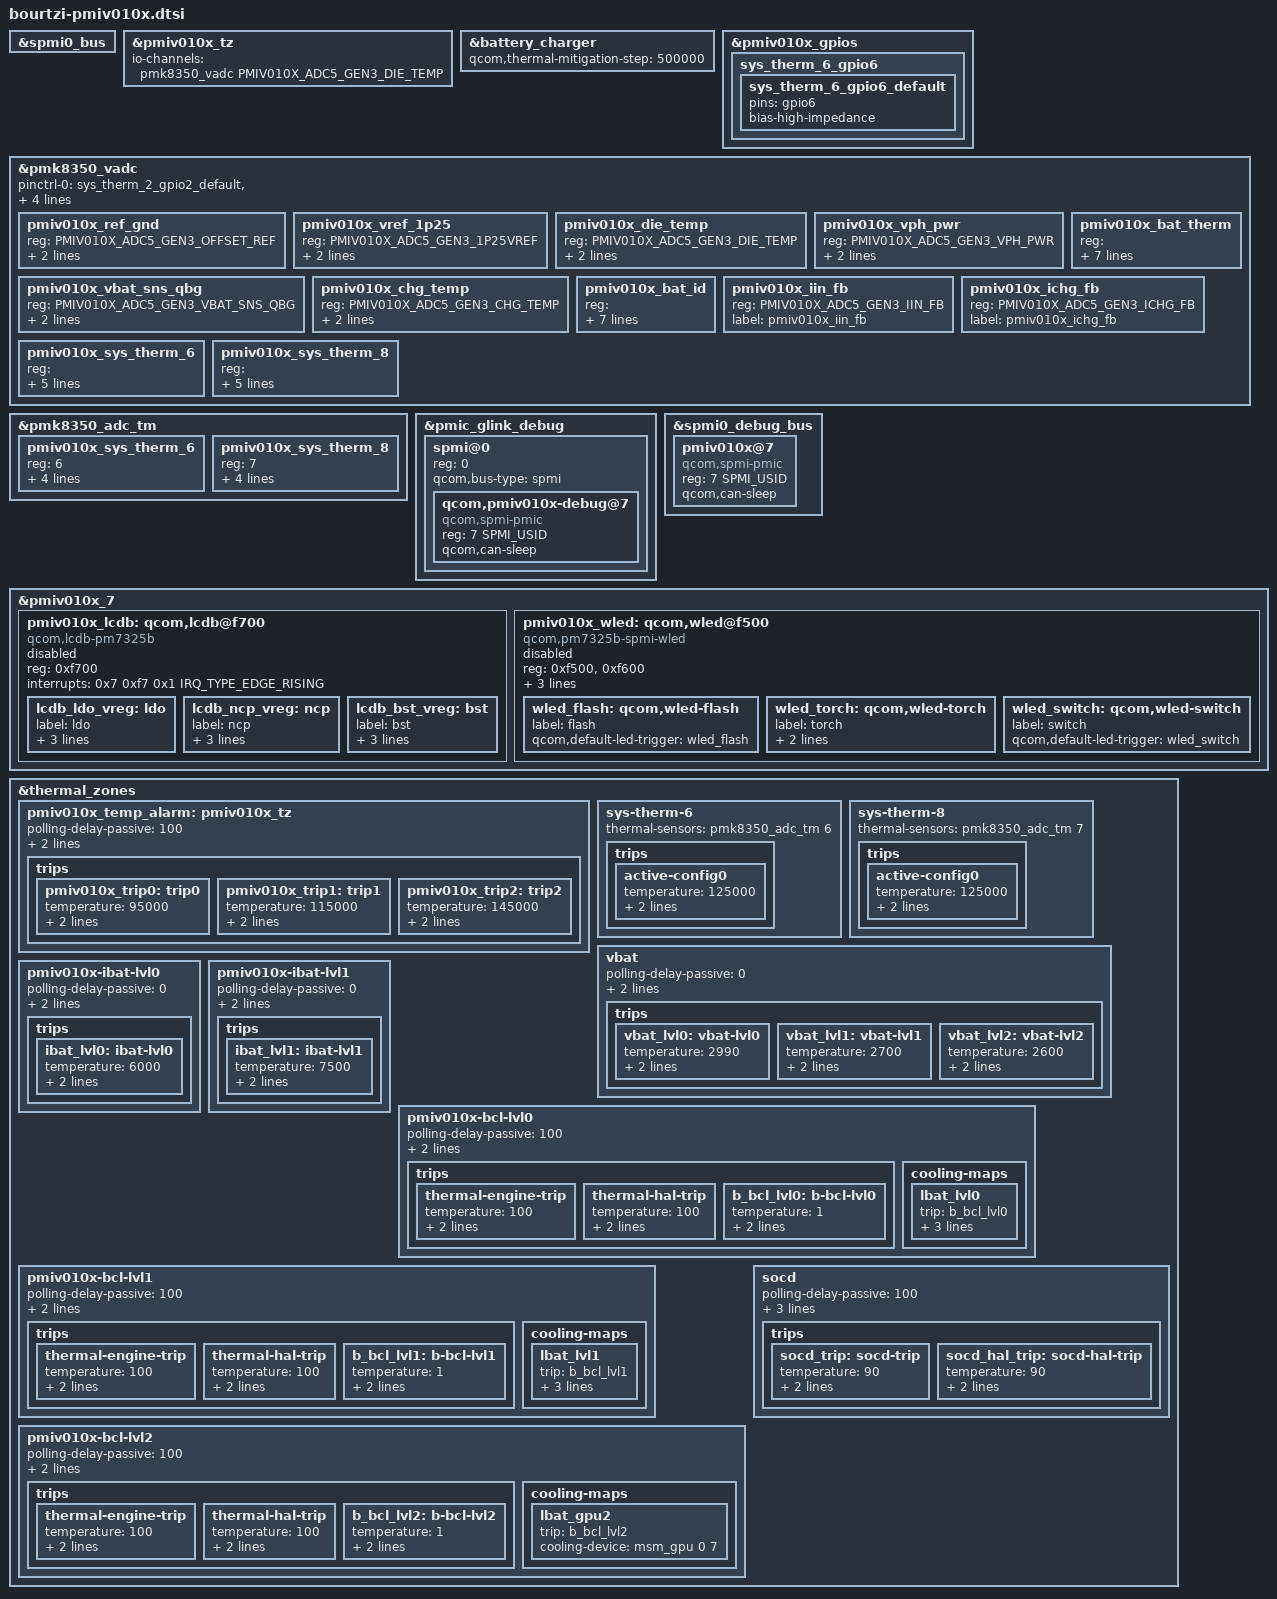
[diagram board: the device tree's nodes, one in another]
// SPDX-License-Identifier: BSD-3-Clause
/*
 * Copyright (c) Qualcomm Technologies, Inc. and/or its subsidiaries.
 */

#include <dt-bindings/iio/qcom,spmi-vadc.h>
#include <dt-bindings/iio/qcom,spmi-adc5-gen3-pmiv010x.h>
#include <dt-bindings/thermal/thermal.h>

&spmi0_bus {
	#include "pmiv010x.dtsi"
};

&pmiv010x_tz {
	io-channels = <&pmk8350_vadc PMIV010X_ADC5_GEN3_DIE_TEMP>;
	io-channel-names = "thermal";
};

&battery_charger {
	#cooling-cells = <2>;
	qcom,thermal-mitigation-step = <500000>;
};

&pmiv010x_gpios {
	sys_therm_6_gpio6 {
		sys_therm_6_gpio6_default: sys_therm_6_gpio6_default {
			pins = "gpio6";
			bias-high-impedance;
		};
	};
};

&pmk8350_vadc {
	pinctrl-0 = <&sys_therm_2_gpio2_default>,
		    <&sys_therm_3_gpio2_default>,
		    <&sys_therm_4_gpio1_default>,
		    <&sys_therm_5_gpio4_default>,
		    <&sys_therm_6_gpio6_default>;
	pinctrl-names = "default";

	pmiv010x_ref_gnd {
		reg = <PMIV010X_ADC5_GEN3_OFFSET_REF>;
		label = "pmiv010x_ref_gnd";
		qcom,pre-scaling = <1 1>;
	};

	pmiv010x_vref_1p25 {
		reg = <PMIV010X_ADC5_GEN3_1P25VREF>;
		label = "pmiv010x_vref_1p25";
		qcom,pre-scaling = <1 1>;
	};

	pmiv010x_die_temp {
		reg = <PMIV010X_ADC5_GEN3_DIE_TEMP>;
		label = "pmiv010x_die_temp";
		qcom,pre-scaling = <1 1>;
	};

	pmiv010x_vph_pwr {
		reg = <PMIV010X_ADC5_GEN3_VPH_PWR>;
		label = "pmiv010x_vph_pwr";
		qcom,pre-scaling = <1 3>;
	};

	pmiv010x_vbat_sns_qbg {
		reg = <PMIV010X_ADC5_GEN3_VBAT_SNS_QBG>;
		label = "pmiv010x_vbat_sns";
		qcom,pre-scaling = <1 3>;
	};

	pmiv010x_chg_temp {
		reg = <PMIV010X_ADC5_GEN3_CHG_TEMP>;
		label = "pmiv010x_chg_temp";
		qcom,pre-scaling = <1 1>;
	};

	pmiv010x_bat_therm {
		reg = <PMIV010X_ADC5_GEN3_AMUX_THM1_BATT_THERM_100K_PU>;
		label = "pmiv010x_bat_therm";
		qcom,ratiometric;
		qcom,hw-settle-time = <200>;
		qcom,pre-scaling = <1 1>;
		qcom,scale-fn-type = <ADC_SCALE_HW_CALIB_PM5_GEN3_BATT_THERM_100K>;
	};

	pmiv010x_bat_id {
		reg = <PMIV010X_ADC5_GEN3_AMUX_THM2_BATT_ID_100K_PU>;
		label = "pmiv010x_bat_id";
		qcom,ratiometric;
		qcom,hw-settle-time = <200>;
		qcom,pre-scaling = <1 1>;
		qcom,scale-fn-type = <ADC_SCALE_HW_CALIB_PM5_GEN3_BATT_ID_100K>;
	};

	pmiv010x_iin_fb {
		reg = <PMIV010X_ADC5_GEN3_IIN_FB>;
		label = "pmiv010x_iin_fb";
	};

	pmiv010x_ichg_fb {
		reg = <PMIV010X_ADC5_GEN3_ICHG_FB>;
		label = "pmiv010x_ichg_fb";
	};

	pmiv010x_sys_therm_6 {
		reg = <PMIV010X_ADC5_GEN3_AMUX_THM6_GPIO6_100K_PU>;
		label = "pmiv010x_sys_therm_6";
		qcom,ratiometric;
		qcom,hw-settle-time = <200>;
		qcom,pre-scaling = <1 1>;
	};

	pmiv010x_sys_therm_8 {
		reg = <PMIV010X_ADC5_GEN3_AMUX_THM4_USB_THERM_100K_PU>;
		label = "pmiv010x_sys_therm_8";
		qcom,ratiometric;
		qcom,hw-settle-time = <200>;
		qcom,pre-scaling = <1 1>;
	};
};

&pmk8350_adc_tm {
	pmiv010x_sys_therm_6 {
		reg = <6>;
		io-channels = <&pmk8350_vadc PMIV010X_ADC5_GEN3_AMUX_THM6_GPIO6_100K_PU>;
		qcom,ratiometric;
		qcom,hw-settle-time-us = <200>;
	};

	pmiv010x_sys_therm_8 {
		reg = <7>;
		io-channels = <&pmk8350_vadc PMIV010X_ADC5_GEN3_AMUX_THM4_USB_THERM_100K_PU>;
		qcom,ratiometric;
		qcom,hw-settle-time-us = <200>;
	};
};

&pmic_glink_debug {
	spmi@0 {
		reg = <0>;
		#address-cells = <2>;
		#size-cells = <0>;
		qcom,bus-type = "spmi";

		qcom,pmiv010x-debug@7 {
			compatible = "qcom,spmi-pmic";
			reg = <7 SPMI_USID>;
			qcom,can-sleep;
		};
	};
};

&spmi0_debug_bus {
	pmiv010x@7 {
		compatible = "qcom,spmi-pmic";
		reg = <7 SPMI_USID>;
		#address-cells = <2>;
		#size-cells = <0>;
		qcom,can-sleep;
	};
};

&pmiv010x_7 {
	pmiv010x_lcdb: qcom,lcdb@f700 {
		compatible = "qcom,lcdb-pm7325b";
		#address-cells = <1>;
		#size-cells = <0>;
		reg = <0xf700>;
		interrupts = <0x7 0xf7 0x1 IRQ_TYPE_EDGE_RISING>;
		interrupt-names = "sc-irq";
		status = "disabled";

		lcdb_ldo_vreg: ldo {
			label = "ldo";
			regulator-name = "lcdb_ldo";
			regulator-min-microvolt = <4400000>;
			regulator-max-microvolt = <6000000>;
		};

		lcdb_ncp_vreg: ncp {
			label = "ncp";
			regulator-name = "lcdb_ncp";
			regulator-min-microvolt = <4400000>;
			regulator-max-microvolt = <6000000>;
		};

		lcdb_bst_vreg: bst {
			label = "bst";
			regulator-name = "lcdb_bst";
			regulator-min-microvolt = <4700000>;
			regulator-max-microvolt = <6400000>;
		};
	};

	pmiv010x_wled: qcom,wled@f500 {
		compatible = "qcom,pm7325b-spmi-wled";
		reg = <0xf500>, <0xf600>;
		reg-names = "wled-ctrl-base", "wled-sink-base";
		label = "backlight";
		qcom,auto-calibration;
		qcom,slew-ramp-time = <256>;
		status = "disabled";

		wled_flash: qcom,wled-flash {
			label = "flash";
			qcom,default-led-trigger = "wled_flash";
		};

		wled_torch: qcom,wled-torch {
			label = "torch";
			qcom,default-led-trigger = "wled_torch";
			qcom,wled-torch-timer = <1200>;
		};

		wled_switch: qcom,wled-switch {
			label = "switch";
			qcom,default-led-trigger = "wled_switch";
		};
	};
};

&thermal_zones {
	pmiv010x_temp_alarm: pmiv010x_tz {
		polling-delay-passive = <100>;
		polling-delay = <0>;
		thermal-sensors = <&pmiv010x_tz>;
		trips {
			pmiv010x_trip0: trip0 {
				temperature = <95000>;
				hysteresis = <0>;
				type = "passive";
			};

			pmiv010x_trip1: trip1 {
				temperature = <115000>;
				hysteresis = <0>;
				type = "passive";
			};

			pmiv010x_trip2: trip2 {
				temperature = <145000>;
				hysteresis = <0>;
				type = "critical";
			};
		};
	};

	sys-therm-6 {
		thermal-sensors = <&pmk8350_adc_tm 6>;

		trips {
			active-config0 {
				temperature = <125000>;
				hysteresis = <1000>;
				type = "passive";
			};
		};
	};

	sys-therm-8 {
		thermal-sensors = <&pmk8350_adc_tm 7>;

		trips {
			active-config0 {
				temperature = <125000>;
				hysteresis = <1000>;
				type = "passive";
			};
		};
	};

	vbat {
		polling-delay-passive = <0>;
		polling-delay = <0>;
		thermal-sensors = <&pmiv010x_bcl 2>;

		trips {
			vbat_lvl0:vbat-lvl0 {
				temperature = <2990>;
				hysteresis = <100>;
				type = "passive";
			};

			vbat_lvl1:vbat-lvl1 {
				temperature = <2700>;
				hysteresis = <100>;
				type = "passive";
			};

			vbat_lvl2:vbat-lvl2 {
				temperature = <2600>;
				hysteresis = <100>;
				type = "passive";
			};
		};
	};

	pmiv010x-ibat-lvl0 {
		polling-delay-passive = <0>;
		polling-delay = <0>;
		thermal-sensors = <&pmiv010x_bcl 0>;

		trips {
			ibat_lvl0:ibat-lvl0 {
				temperature = <6000>;
				hysteresis = <200>;
				type = "passive";
			};
		};
	};

	pmiv010x-ibat-lvl1 {
		polling-delay-passive = <0>;
		polling-delay = <0>;
		thermal-sensors = <&pmiv010x_bcl 1>;

		trips {
			ibat_lvl1:ibat-lvl1 {
				temperature = <7500>;
				hysteresis = <200>;
				type = "passive";
			};
		};
	};

	pmiv010x-bcl-lvl0 {
		polling-delay-passive = <100>;
		polling-delay = <0>;
		thermal-sensors = <&pmiv010x_bcl 5>;

		trips {
			thermal-engine-trip {
				temperature = <100>;
				hysteresis = <0>;
				type = "passive";
			};

			thermal-hal-trip {
				temperature = <100>;
				hysteresis = <0>;
				type = "passive";
			};

			b_bcl_lvl0: b-bcl-lvl0 {
				temperature = <1>;
				hysteresis = <0>;
				type = "passive";
			};
		};

		cooling-maps {
			lbat_lvl0 {
				trip = <&b_bcl_lvl0>;
				cooling-device = <&msm_gpu 0 2>,
						<&modem_lte_dsc 8 8>,
						<&modem_nr_dsc 6 6>,
						<&modem_nr_scg_dsc 3 3>;
			};
		};
	};

	pmiv010x-bcl-lvl1 {
		polling-delay-passive = <100>;
		polling-delay = <0>;
		thermal-sensors = <&pmiv010x_bcl 6>;

		trips {
			thermal-engine-trip {
				temperature = <100>;
				hysteresis = <0>;
				type = "passive";
			};

			thermal-hal-trip {
				temperature = <100>;
				hysteresis = <0>;
				type = "passive";
			};

			b_bcl_lvl1: b-bcl-lvl1 {
				temperature = <1>;
				hysteresis = <0>;
				type = "passive";
			};
		};

		cooling-maps {
			lbat_lvl1 {
				trip = <&b_bcl_lvl1>;
				cooling-device = <&msm_gpu 0 3>,
						<&modem_lte_dsc 10 10>,
						<&modem_nr_dsc 9 9>,
						<&modem_nr_scg_dsc 10 10>;
			};
		};
	};

	pmiv010x-bcl-lvl2 {
		polling-delay-passive = <100>;
		polling-delay = <0>;
		thermal-sensors = <&pmiv010x_bcl 7>;

		trips {
			thermal-engine-trip {
				temperature = <100>;
				hysteresis = <0>;
				type = "passive";
			};

			thermal-hal-trip {
				temperature = <100>;
				hysteresis = <0>;
				type = "passive";
			};

			b_bcl_lvl2: b-bcl-lvl2 {
				temperature = <1>;
				hysteresis = <0>;
				type = "passive";
			};
		};

		cooling-maps {
			lbat_gpu2 {
				trip = <&b_bcl_lvl2>;
				cooling-device = <&msm_gpu 0 7>;
			};
		};
	};

	socd {
		polling-delay-passive = <100>;
		polling-delay = <0>;
		thermal-governor = "step_wise";
		thermal-sensors = <&bcl_soc>;

		trips {
			socd_trip:socd-trip {
				temperature = <90>;
				hysteresis = <0>;
				type = "passive";
			};

			socd_hal_trip:socd-hal-trip {
				temperature = <90>;
				hysteresis = <0>;
				type = "passive";
			};
		};
	};
};
